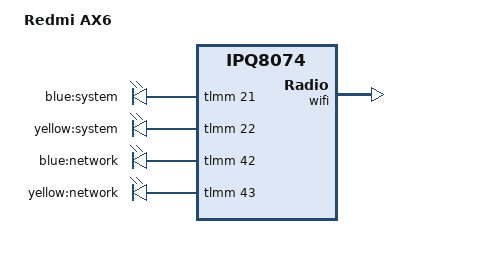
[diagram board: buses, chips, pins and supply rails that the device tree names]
// SPDX-License-Identifier: GPL-2.0-or-later OR MIT
/* Copyright (c) 2021, Zhijun You <hujy652@gmail.com> */

/dts-v1/;

#include "ipq8071-ax3600.dtsi"

/ {
	model = "Redmi AX6";
	compatible = "redmi,ax6", "qcom,ipq8074";

	chosen {
		bootargs-append = " root=/dev/ubiblock0_1";
	};

	leds {
		compatible = "gpio-leds";

		led_system_blue: system-blue {
			label = "blue:system";
			gpios = <&tlmm 21 GPIO_ACTIVE_HIGH>;
		};

		led_system_yellow: system-yellow {
			label = "yellow:system";
			gpios = <&tlmm 22 GPIO_ACTIVE_HIGH>;
		};

		network-blue {
			label = "blue:network";
			gpios = <&tlmm 42 GPIO_ACTIVE_HIGH>;
		};

		network-yellow {
			label = "yellow:network";
			gpios = <&tlmm 43 GPIO_ACTIVE_HIGH>;
		};
	};
};

/* AX6 with merged partition layout (不死 uboot):
 * bdata, pstore, and ubi_kernel are removed.
 * rootfs starts at 0x880000 and extends to the end of 128MiB NAND.
 * UBI layout: vol0=kernel, vol1=rootfs(squashfs), vol2=rootfs_data(ubifs)
 */
&bdata {
	status = "disabled";
};

&pstore {
	status = "disabled";
};

&ubi_kernel {
	status = "disabled";
};

&rootfs {
	reg = <0x880000 0x7600000>;
};

&wifi {
	qcom,ath11k-calibration-variant = "Redmi-AX6";
};
